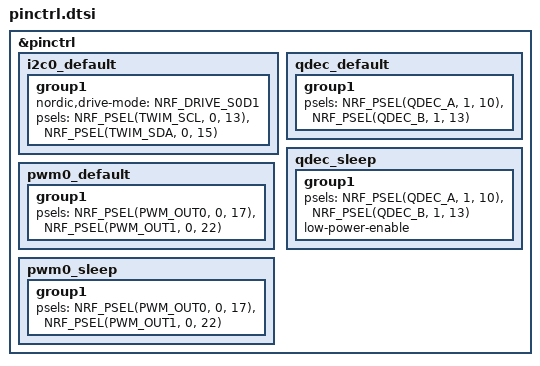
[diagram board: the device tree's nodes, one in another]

&pinctrl {
	i2c0_default: i2c0_default {
		group1 {
                        nordic,drive-mode = <NRF_DRIVE_S0D1>;
			psels = <NRF_PSEL(TWIM_SCL, 0, 13)>,
				<NRF_PSEL(TWIM_SDA, 0, 15)>;
		};
	};
	qdec_default: qdec_default {
		group1 {
			psels = <NRF_PSEL(QDEC_A, 1, 10)>,
				<NRF_PSEL(QDEC_B, 1, 13)>;
		};
	};
	qdec_sleep: qdec_sleep {
		group1 {
			psels = <NRF_PSEL(QDEC_A, 1, 10)>,
				<NRF_PSEL(QDEC_B, 1, 13)>;
			low-power-enable;
		};
	};
	pwm0_default: pwm0_default {
		group1 {
			psels = <NRF_PSEL(PWM_OUT0, 0, 17)>,
				<NRF_PSEL(PWM_OUT1, 0, 22)>;
                        /delete-property/ nordic,invert;
		};
	};
	pwm0_sleep: pwm0_sleep {
		group1 {
			psels = <NRF_PSEL(PWM_OUT0, 0, 17)>,
				<NRF_PSEL(PWM_OUT1, 0, 22)>;
		};
	};

};
